VERSION ""

NS_ :

BS_:

BU_: XXX

BO_ 176 WHEELS_0: 6 XXX
 SG_ WHEEL_SPEED_1 : 7|16@0+ (1,0) [0|65535] "" XXX
 SG_ WHEEL_SPEED_2 : 23|16@0+ (1,0) [0|65535] "" XXX

BO_ 705 THROTTLE_PEDAL_: 8 XXX
 SG_ THROTTLE_PEDAL : 55|8@0+ (1,0) [0|65535] "" XXX

BO_ 34 STEERING_TORQUE: 8 XXX
 SG_ TORQUE_1 : 56|8@1- (1,-45) [-255|255] "" XXX
 SG_ TORQUE_0 : 1|10@0+ (1,-512) [-255|255] "" XXX

BO_ 1552 SPEED_KPH_: 8 XXX
 SG_ NEW_SIGNAL_2 : 1|10@0+ (1,-520) [-512|512] "" XXX
 SG_ SPEED_MPH_ : 16|8@1+ (0.621371,0) [0|255] "" XXX

BO_ 178 WHEELS_1: 6 XXX
 SG_ WHEEL_SPEED_3 : 7|16@0+ (1,0) [0|65535] "" XXX
 SG_ WHEEL_SPEED_4 : 23|16@0+ (1,0) [0|65535] "" XXX

BO_ 37 STEERING_LIKE_: 8 XXX
 SG_ VEHICLE_STEERING_ANGLE : 3|12@0- (1,0) [0|4095] "" XXX
 SG_ NEW_SIGNAL_1 : 31|2@0+ (1,0) [0|3] "" XXX

BO_ 947 THROTTLE_2: 3 XXX
 SG_ THROTTLE_2 : 16|8@1+ (1.5,-60) [0|255] "" XXX

BO_ 548 BRAKE: 8 XXX
 SG_ BRAKE : 47|8@0+ (1,0) [0|255] "" XXX

BO_ 32 NEW_MSG_2: 8 XXX
 SG_ NEW_SIGNAL_2 : 45|7@1- (1,0) [0|255] "" XXX

BO_ 35 STEERING_LIKE_1: 8 XXX
 SG_ NEW_SIGNAL_2 : 1|10@0+ (1,0) [0|1023] "" XXX
 SG_ NEW_SIGNAL_1 : 41|10@0- (1,0) [0|255] "" XXX

BO_ 180 SPEED_THROTTLE_LIKE: 8 XXX
 SG_ SPEED_THROTTLE_LIKE : 40|8@1+ (1,0) [0|255] "" XXX

BO_ 708 ENGINE_SPEED: 8 XXX
 SG_ ENGINE_SPEED : 7|16@0+ (1,0) [0|65535] "" XXX

BO_ 547 STATIC: 8 XXX
 SG_ UNKNOWN_ : 63|8@0+ (1,0) [0|255] "" XXX
 SG_ UNKNOWN : 0|8@1+ (1,0) [0|255] "" XXX

BO_ 720 UNKNOWN: 8 XXX
 SG_ UNDOCUMENTED : 7|10@0+ (1,0) [0|255] "" XXX

BO_ 928 STATIC_1: 8 XXX

BO_ 1088 STATIC_2: 8 XXX

BO_ 1090 STATIC_3: 8 XXX
 SG_ NEW_SIGNAL_1 : 8|8@1+ (1,0) [0|255] "" XXX
 SG_ NEW_SIGNAL_2 : 0|8@1+ (1,0) [0|255] "" XXX

BO_ 951 STATIC_4: 8 XXX

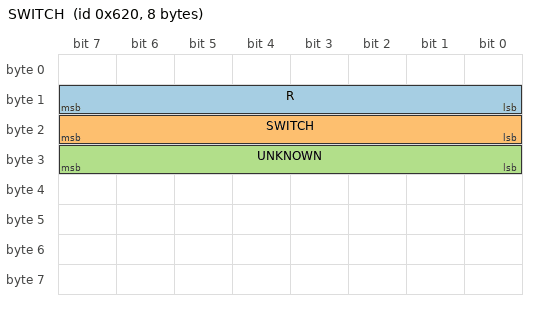
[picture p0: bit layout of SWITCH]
BO_ 1568 SWITCH: 8 XXX
 SG_ R : 15|8@0+ (1,0) [0|511] "" XXX
 SG_ SWITCH : 23|8@0+ (1,0) [0|255] "" XXX
 SG_ UNKNOWN : 31|8@0+ (1,0) [0|255] "" XXX

BO_ 896 STATIC_5: 8 XXX

BO_ 906 STATIC_6: 8 XXX

BO_ 921 STATIC_7: 8 XXX

BO_ 929 STATIC_8: 8 XXX
 SG_ NEW_SIGNAL_1 : 40|8@1+ (1,0) [0|255] "" XXX

BO_ 944 STATIC_9: 8 XXX
 SG_ NEW_SIGNAL_1 : 24|8@1+ (1,0) [0|255] "" XXX

BO_ 945 STATIC_10: 8 XXX
 SG_ NEW_SIGNAL_1 : 24|8@1+ (1,0) [0|255] "" XXX
 SG_ APERIODIC : 32|8@1+ (1,0) [0|255] "" XXX

BO_ 1059 STATIC_11: 8 XXX

BO_ 1217 STATIC_12: 8 XXX

BO_ 1219 STATIC_13: 8 XXX

BO_ 1569 STATIC_16: 8 XXX
 SG_ NEW_SIGNAL_1 : 7|16@0+ (1,0) [0|65535] "" XXX

BO_ 948 PRND: 8 XXX

BO_ 1553 ODOMETER: 8 XXX
 SG_ MILE_MARKER : 7|16@0+ (1,0) [0|65535] "" XXX
 SG_ ODOMETER_ : 23|48@0+ (1,0) [0|4294967295] "" XXX
